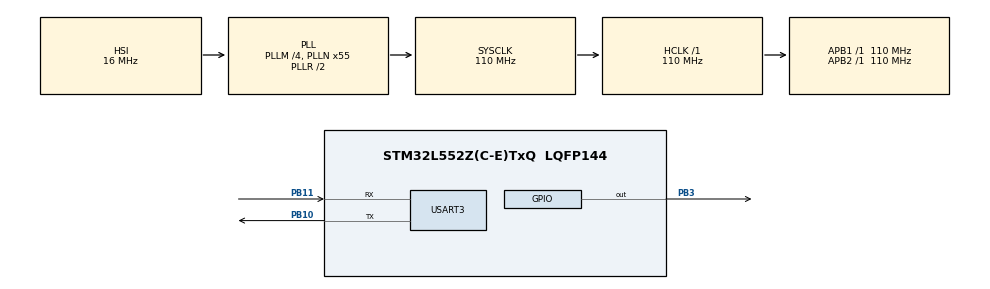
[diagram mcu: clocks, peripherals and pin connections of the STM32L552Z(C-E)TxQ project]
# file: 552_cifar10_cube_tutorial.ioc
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Mcu.Family=STM32L5
Mcu.Name=STM32L552Z(C-E)TxQ
Mcu.Package=LQFP144
NVIC.PriorityGroup=NVIC_PRIORITYGROUP_3
PB10.Mode=Asynchronous
PB10.Signal=USART3_TX
PB11.Mode=Asynchronous
PB11.Signal=USART3_RX
PB3\ (JTDO/TRACESWO).GPIO_PuPd=GPIO_PULLUP
PB3\ (JTDO/TRACESWO).GPIO_Speed=GPIO_SPEED_FREQ_HIGH
PB3\ (JTDO/TRACESWO).PinState=GPIO_PIN_SET
PB3\ (JTDO/TRACESWO).Signal=GPIO_Output
ProjectManager.HeapSize=0x200
ProjectManager.StackSize=0x800
ProjectManager.TargetToolchain=STM32CubeIDE
RCC.ADCFreq_Value=6000000
RCC.AHBFreq_Value=110000000
RCC.APB1Freq_Value=110000000
RCC.APB1TimFreq_Value=110000000
RCC.APB2Freq_Value=110000000
RCC.APB2TimFreq_Value=110000000
RCC.CortexFreq_Value=110000000
RCC.HCLKFreq_Value=110000000
RCC.HSE_VALUE=16000000
RCC.HSI48_VALUE=48000000
RCC.HSI_VALUE=16000000
RCC.LSE_VALUE=32768
RCC.MSI_VALUE=4000000
RCC.PLLM=4
RCC.PLLM1=2
RCC.PLLM2=2
RCC.PLLN=55
RCC.PLLSAI1M=4
RCC.PLLSAI1N=48
RCC.PLLSAI1P=RCC_PLLP_DIV17
RCC.PLLSAI1Q=RCC_PLLQ_DIV4
RCC.PLLSAI1R=RCC_PLLR_DIV8
RCC.PLLSourceVirtual=RCC_PLLSOURCE_HSI
RCC.RTCClockSelection=RCC_RTCCLKSOURCE_LSE
RCC.SYSCLKFreq_VALUE=110000000
RCC.SYSCLKSource=RCC_SYSCLKSOURCE_PLLCLK
RCC.USBFreq_Value=12000000
RCC.VCOOutputFreq_Value=220000000
STMicroelectronics.X-CUBE-AI.5.2.0.ActivationBufferSizeList=21610
STMicroelectronics.X-CUBE-AI.5.2.0.HeapSize=0x200
STMicroelectronics.X-CUBE-AI.5.2.0.InternalRamActivationBufferMaxSize=AI_FACEDETECTION_DATA_ACTIVATIONS_SIZE
STMicroelectronics.X-CUBE-AI.5.2.0.LatestDirectoryUsed-bb0c6e3ef93466fd36f1bdd7d4e968cf484981a8f980f26bfb26ec4fb6149137=C\:\\Users\\NOTA0801\\Desktop\\NOTA\\[PRJ] DL Compiler\\NXP\\eIQ glow vs tflite on RT1050
STMicroelectronics.X-CUBE-AI.5.2.0.MaximumNumberOfInputLayer=1
STMicroelectronics.X-CUBE-AI.5.2.0.MaximumNumberOfOutputLayer=1
STMicroelectronics.X-CUBE-AI.5.2.0.MaximumSizeOfInputLayer=AI_FACEDETECTION_IN_1_SIZE_BYTES
STMicroelectronics.X-CUBE-AI.5.2.0.MaximumSizeOfOutputLayer=AI_FACEDETECTION_OUT_1_SIZE_BYTES
STMicroelectronics.X-CUBE-AI.5.2.0.ModelActualCompression-bb0c6e3ef93466fd36f1bdd7d4e968cf484981a8f980f26bfb26ec4fb6149137=0.0
STMicroelectronics.X-CUBE-AI.5.2.0.ModelCompression-bb0c6e3ef93466fd36f1bdd7d4e968cf484981a8f980f26bfb26ec4fb6149137=1
STMicroelectronics.X-CUBE-AI.5.2.0.ModelFlashOccupation-bb0c6e3ef93466fd36f1bdd7d4e968cf484981a8f980f26bfb26ec4fb6149137=89992
STMicroelectronics.X-CUBE-AI.5.2.0.ModelHashList=bb0c6e3ef93466fd36f1bdd7d4e968cf484981a8f980f26bfb26ec4fb6149137
STMicroelectronics.X-CUBE-AI.5.2.0.ModelKind-bb0c6e3ef93466fd36f1bdd7d4e968cf484981a8f980f26bfb26ec4fb6149137=TFLITE
STMicroelectronics.X-CUBE-AI.5.2.0.ModelMacc-bb0c6e3ef93466fd36f1bdd7d4e968cf484981a8f980f26bfb26ec4fb6149137=12340542
STMicroelectronics.X-CUBE-AI.5.2.0.ModelName-bb0c6e3ef93466fd36f1bdd7d4e968cf484981a8f980f26bfb26ec4fb6149137=facedetection
STMicroelectronics.X-CUBE-AI.5.2.0.ModelNameList=facedetection
STMicroelectronics.X-CUBE-AI.5.2.0.ModelRamOccupation-bb0c6e3ef93466fd36f1bdd7d4e968cf484981a8f980f26bfb26ec4fb6149137=21610
STMicroelectronics.X-CUBE-AI.5.2.0.ModelStructureFile-bb0c6e3ef93466fd36f1bdd7d4e968cf484981a8f980f26bfb26ec4fb6149137=C\:\\Users\\NOTA0801\\Desktop\\NOTA\\[PRJ] DL Compiler\\NXP\\eIQ glow vs tflite on RT1050\\cifar10_model.tflite
STMicroelectronics.X-CUBE-AI.5.2.0.ModelType-bb0c6e3ef93466fd36f1bdd7d4e968cf484981a8f980f26bfb26ec4fb6149137=Saved model
STMicroelectronics.X-CUBE-AI.5.2.0.StackSize=0x800
STMicroelectronics.X-CUBE-AI.5.2.0.WorkingBufferStartAddrList=0xFFFFFFFF
STMicroelectronics.X-CUBE-AI.5.2.0.XAaCUBEAaAICcArtificialOoIntelligenceJjCore=true
TIM16.Prescaler=109
USART3.VirtualMode-Asynchronous=VM_ASYNC
VP_CRC_VS_CRC.Mode=CRC_Activate
VP_PWR_VS_DBSignals.Mode=DisableDeadBatterySignals
VP_STMicroelectronics.X-CUBE-AI_VS_ArtificialOoIntelligenceJjXAaCUBEAaAI_5.2.0.Mode=ArtificialOoIntelligenceJjXAaCUBEAaAI
VP_TIM16_VS_ClockSourceINT.Mode=Enable_Timer
board=STM32L552E-EV

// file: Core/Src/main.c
/* USER CODE BEGIN Header */
/**
  ******************************************************************************
  * @file           : main.c
  * @brief          : Main program body
  ******************************************************************************
  * @attention
  *
  * <h2><center>&copy; Copyright (c) 2021 STMicroelectronics.
  * All rights reserved.</center></h2>
  *
  * This software component is licensed by ST under Ultimate Liberty license
  * SLA0044, the "License"; You may not use this file except in compliance with
  * the License. You may obtain a copy of the License at:
  *                             www.st.com/SLA0044
  *
  ******************************************************************************
  */
/* USER CODE END Header */
#include "main.h"

/* USER CODE BEGIN Includes */
#include <stdio.h>

#include "ai_datatypes_defines.h"
#include "ai_platform.h"
#include "facedetection.h"  // {network_name}.h
#include "facedetection_data.h"  // {network_name}_data.h
#include "automobile_image.h"
/* USER CODE END Includes */

/* USER CODE BEGIN PD */
const char* labels[] = {
    "airplane",
    "automobile",
    "bird",
    "cat",
    "deer",
    "dog",
    "frog",
    "horse",
    "ship",
    "truck"
};
/* USER CODE END PD */

CRC_HandleTypeDef hcrc;

TIM_HandleTypeDef htim16;

UART_HandleTypeDef huart3;

void SystemClock_Config(void);
static void MX_GPIO_Init(void);
static void MX_USART3_UART_Init(void);
static void MX_TIM16_Init(void);
static void MX_CRC_Init(void);

int main(void)
{
  /* USER CODE BEGIN 1 */
  char buf[50];
  int buf_len = 0;
  ai_error ai_err;
  ai_i32 nbatch;
  uint32_t timestamp;
  int max_index;
  uint8_t value = 0;
  unsigned long inference_time = 0;

  // Chunk of memory used to hold intermediate values for neural network
  // {network_name}_data.h, {network_name}.h 파일을 참고해서 자기 모델에 맞게 변수를 넣어주세요.
  AI_ALIGNED(4) ai_u8 activations[AI_FACEDETECTION_DATA_ACTIVATIONS_SIZE];

  // Buffers used to store input and output tensors
  AI_ALIGNED(4) ai_i8 in_data[AI_FACEDETECTION_IN_1_SIZE_BYTES];
  AI_ALIGNED(4) ai_i8 out_data[AI_FACEDETECTION_OUT_1_SIZE_BYTES];

  // Pointer to our model
  ai_handle facedetect = AI_HANDLE_NULL;

  // Initialize wrapper structs that hold pointers to data and info about the
  // data (tensor height, width, channels)
  ai_buffer ai_input[AI_FACEDETECTION_IN_NUM] = AI_FACEDETECTION_IN;
  ai_buffer ai_output[AI_FACEDETECTION_OUT_NUM] = AI_FACEDETECTION_OUT;

  // Set working memory and get weights/biases from model
  ai_network_params ai_params = {
	AI_FACEDETECTION_DATA_WEIGHTS(ai_facedetection_data_weights_get()),
	AI_FACEDETECTION_DATA_ACTIVATIONS(activations)
  };

  // Set pointers wrapper structs to our data buffers
  ai_input[0].n_batches = 1;
  ai_input[0].data = AI_HANDLE_PTR(in_data);
  ai_output[0].n_batches = 1;
  ai_output[0].data = AI_HANDLE_PTR(out_data);
  /* USER CODE END 1 */

  /* MCU Configuration--------------------------------------------------------*/

  /* Reset of all peripherals, Initializes the Flash interface and the Systick. */
  HAL_Init();

  /* Configure the system clock */
  SystemClock_Config();

  /* Initialize all configured peripherals */
  MX_GPIO_Init();
  MX_USART3_UART_Init();
  MX_TIM16_Init();
  MX_CRC_Init();
  /* USER CODE BEGIN 2 */
  // Start timer/counter
  HAL_TIM_Base_Start(&htim16);

  // Greetings!
  buf_len = sprintf(buf, "\r\n\r\nSTM32 X-Cube-AI test\r\n");
  HAL_UART_Transmit(&huart3, (uint8_t *)buf, buf_len, 100);

  // Create instance of neural network
  ai_err = ai_facedetection_create(&facedetect, AI_FACEDETECTION_DATA_CONFIG);
  if (ai_err.type != AI_ERROR_NONE)
  {
    buf_len = sprintf(buf, "Error: could not create NN instance\r\n");
    HAL_UART_Transmit(&huart3, (uint8_t *)buf, buf_len, 100);
    while(1);
  }

  // Initialize neural network
  if (!ai_facedetection_init(facedetect, &ai_params))
  {
    buf_len = sprintf(buf, "Error: could not initialize NN\r\n");
    HAL_UART_Transmit(&huart3, (uint8_t *)buf, buf_len, 100);
    while(1);
  }
  /* USER CODE END 2 */

  /* Infinite loop */
  /* USER CODE BEGIN WHILE */
  while (1)
  {
	for (uint32_t i = 0; i < AI_FACEDETECTION_IN_1_SIZE; i++)
	{
	  ((ai_u8 *)in_data)[i] = (ai_u8)image_data[i];
	}

	// Get current timestamp
	timestamp = HAL_GetTick();

	// Perform inference
	nbatch = ai_facedetection_run(facedetect, &ai_input[0], &ai_output[0]);
	if (nbatch != 1) {
	  buf_len = sprintf(buf, "Error: could not run inference\r\n");
	  HAL_UART_Transmit(&huart3, (uint8_t *)buf, buf_len, 100);
	}

	for(int i=0; i<10; i++){
		if(value < (uint8_t)out_data[i]){
			value = (uint8_t)out_data[i];
			max_index = i;
		}
	}
	inference_time = HAL_GetTick() - timestamp;

	// Print output of neural network along with inference time (microseconds)
	buf_len = sprintf(buf, "Detected : %s (confidence : %.2f%%)\r\n", labels[max_index], (float)value/256*100);
	HAL_UART_Transmit(&huart3, (uint8_t *)buf, buf_len, 100);
	buf_len = sprintf(buf, "Duration : %lu㎳\r\n\r\n\r\n", inference_time, inference_time/1000);
	HAL_UART_Transmit(&huart3, (uint8_t *)buf, buf_len, 100);

	// Wait before doing it again
	HAL_Delay(500);
    /* USER CODE END WHILE */

  }
}

void SystemClock_Config(void)
{
  RCC_OscInitTypeDef RCC_OscInitStruct = {0};
  RCC_ClkInitTypeDef RCC_ClkInitStruct = {0};

  /** Configure the main internal regulator output voltage
  */
  if (HAL_PWREx_ControlVoltageScaling(PWR_REGULATOR_VOLTAGE_SCALE0) != HAL_OK)
  {
    Error_Handler();
  }
  /** Initializes the RCC Oscillators according to the specified parameters
  * in the RCC_OscInitTypeDef structure.
  */
  RCC_OscInitStruct.OscillatorType = RCC_OSCILLATORTYPE_HSI;
  RCC_OscInitStruct.HSIState = RCC_HSI_ON;
  RCC_OscInitStruct.HSICalibrationValue = RCC_HSICALIBRATION_DEFAULT;
  RCC_OscInitStruct.PLL.PLLState = RCC_PLL_ON;
  RCC_OscInitStruct.PLL.PLLSource = RCC_PLLSOURCE_HSI;
  RCC_OscInitStruct.PLL.PLLM = 4;
  RCC_OscInitStruct.PLL.PLLN = 55;
  RCC_OscInitStruct.PLL.PLLP = RCC_PLLP_DIV7;
  RCC_OscInitStruct.PLL.PLLQ = RCC_PLLQ_DIV2;
  RCC_OscInitStruct.PLL.PLLR = RCC_PLLR_DIV2;
  if (HAL_RCC_OscConfig(&RCC_OscInitStruct) != HAL_OK)
  {
    Error_Handler();
  }
  /** Initializes the CPU, AHB and APB buses clocks
  */
  RCC_ClkInitStruct.ClockType = RCC_CLOCKTYPE_HCLK|RCC_CLOCKTYPE_SYSCLK
                              |RCC_CLOCKTYPE_PCLK1|RCC_CLOCKTYPE_PCLK2;
  RCC_ClkInitStruct.SYSCLKSource = RCC_SYSCLKSOURCE_PLLCLK;
  RCC_ClkInitStruct.AHBCLKDivider = RCC_SYSCLK_DIV1;
  RCC_ClkInitStruct.APB1CLKDivider = RCC_HCLK_DIV1;
  RCC_ClkInitStruct.APB2CLKDivider = RCC_HCLK_DIV1;

  if (HAL_RCC_ClockConfig(&RCC_ClkInitStruct, FLASH_LATENCY_5) != HAL_OK)
  {
    Error_Handler();
  }
}

static void MX_CRC_Init(void)
{

  hcrc.Instance = CRC;
  hcrc.Init.DefaultPolynomialUse = DEFAULT_POLYNOMIAL_ENABLE;
  hcrc.Init.DefaultInitValueUse = DEFAULT_INIT_VALUE_ENABLE;
  hcrc.Init.InputDataInversionMode = CRC_INPUTDATA_INVERSION_NONE;
  hcrc.Init.OutputDataInversionMode = CRC_OUTPUTDATA_INVERSION_DISABLE;
  hcrc.InputDataFormat = CRC_INPUTDATA_FORMAT_BYTES;
  if (HAL_CRC_Init(&hcrc) != HAL_OK)
  {
    Error_Handler();
  }

}

static void MX_TIM16_Init(void)
{

  htim16.Instance = TIM16;
  htim16.Init.Prescaler = 109;
  htim16.Init.CounterMode = TIM_COUNTERMODE_UP;
  htim16.Init.Period = 65535;
  htim16.Init.ClockDivision = TIM_CLOCKDIVISION_DIV1;
  htim16.Init.RepetitionCounter = 0;
  htim16.Init.AutoReloadPreload = TIM_AUTORELOAD_PRELOAD_DISABLE;
  if (HAL_TIM_Base_Init(&htim16) != HAL_OK)
  {
    Error_Handler();
  }

}

static void MX_USART3_UART_Init(void)
{

  huart3.Instance = USART3;
  huart3.Init.BaudRate = 115200;
  huart3.Init.WordLength = UART_WORDLENGTH_8B;
  huart3.Init.StopBits = UART_STOPBITS_1;
  huart3.Init.Parity = UART_PARITY_NONE;
  huart3.Init.Mode = UART_MODE_TX_RX;
  huart3.Init.HwFlowCtl = UART_HWCONTROL_NONE;
  huart3.Init.OverSampling = UART_OVERSAMPLING_16;
  huart3.Init.OneBitSampling = UART_ONE_BIT_SAMPLE_DISABLE;
  huart3.Init.ClockPrescaler = UART_PRESCALER_DIV1;
  huart3.AdvancedInit.AdvFeatureInit = UART_ADVFEATURE_NO_INIT;
  if (HAL_UART_Init(&huart3) != HAL_OK)
  {
    Error_Handler();
  }
  if (HAL_UARTEx_SetTxFifoThreshold(&huart3, UART_TXFIFO_THRESHOLD_1_8) != HAL_OK)
  {
    Error_Handler();
  }
  if (HAL_UARTEx_SetRxFifoThreshold(&huart3, UART_RXFIFO_THRESHOLD_1_8) != HAL_OK)
  {
    Error_Handler();
  }
  if (HAL_UARTEx_DisableFifoMode(&huart3) != HAL_OK)
  {
    Error_Handler();
  }

}

static void MX_GPIO_Init(void)
{
  GPIO_InitTypeDef GPIO_InitStruct = {0};

  /* GPIO Ports Clock Enable */
  __HAL_RCC_GPIOB_CLK_ENABLE();

  /*Configure GPIO pin Output Level */
  HAL_GPIO_WritePin(GPIOB, GPIO_PIN_3, GPIO_PIN_SET);

  /*Configure GPIO pin : PB3 */
  GPIO_InitStruct.Pin = GPIO_PIN_3;
  GPIO_InitStruct.Mode = GPIO_MODE_OUTPUT_PP;
  GPIO_InitStruct.Pull = GPIO_PULLUP;
  GPIO_InitStruct.Speed = GPIO_SPEED_FREQ_HIGH;
  HAL_GPIO_Init(GPIOB, &GPIO_InitStruct);

}

void Error_Handler(void)
{
}

/************************ (C) COPYRIGHT STMicroelectronics *****END OF FILE****/
